# STM32L412C8T6 register map
File version: 1.0
STM32L412C8T6,STM32L412C8U6,STM32L412CBT3,STM32L412CBT3P,STM32L412CBT6,STM32L412CBT6P,STM32L412CBT7,STM32L412CBT7P,STM32L412CBU3,STM32L412CBU3P,STM32L412CBU6,STM32L412CBU6P,STM32L412CBU7,STM32L412CBU7P,STM32L412K8T6,STM32L412K8U6,STM32L412KBT3,STM32L412KBT6,STM32L412KBT7,STM32L412KBU3,STM32L412KBU6,STM32L412KBU7,STM32L412R8I6,STM32L412R8T6,STM32L412RBI6,STM32L412RBI6P,STM32L412RBT6,STM32L412RBT6P,STM32L412T8Y6,STM32L412TBY6,STM32L412TBY6P,STM32L422CBT6,STM32L422CBU6,STM32L422KBT6,STM32L422KBU6,STM32L422RBI6,STM32L422RBT6,STM32L422TBY6,STM32L431CBT6,STM32L431CBT7,STM32L431CBU6,STM32L431CBU7,STM32L431CBY6,STM32L431CBY7,STM32L431CCT6,STM32L431CCU6,STM32L431CCY6,STM32L431KBU6,STM32L431KCU6,STM32L431RBI3,STM32L431RBI6,STM32L431RBI7,STM32L431RBT3,STM32L431RBT6,STM32L431RBT7,STM32L431RBY3,STM32L431RBY6,STM32L431RBY7,STM32L431RCI6,STM32L431RCT6,STM32L431RCY6,STM32L431VCI6,STM32L431VCI7,STM32L431VCT6,STM32L431VCT7,STM32L432KBU6,STM32L432KCU6,STM32L433CBT6,STM32L433CBT7,STM32L433CBU6,STM32L433CBU7,STM32L433CBY6,STM32L433CBY7,STM32L433CCT3,STM32L433CCT6,STM32L433CCT7,STM32L433CCU3,STM32L433CCU6,STM32L433CCU7,STM32L433CCY3,STM32L433CCY6,STM32L433CCY7,STM32L433RBI6,STM32L433RBT6,STM32L433RBY6,STM32L433RCI3,STM32L433RCI6,STM32L433RCI7,STM32L433RCT3,STM32L433RCT3P,STM32L433RCT6,STM32L433RCT6P,STM32L433RCT7,STM32L433RCT7P,STM32L433RCY3,STM32L433RCY6,STM32L433RCY7,STM32L433VCI3,STM32L433VCI6,STM32L433VCI7,STM32L433VCT3,STM32L433VCT6,STM32L433VCT7,STM32L442KCU6,STM32L443CCF6,STM32L443CCT6,STM3
Registers are 32-bit, access not given, reset 0x0 unless marked. A register's access mark holds for its fields unless they carry their own. Offsets are from the block's base; lines under a group give offsets from that group; [hi:lo] are bit positions; {n}, {i} and the like mark numbered series; 'fields as' and 'values as' point back to an identical list; <NAME> marks a mode.

## Memory map
0x40000000 TIM2
0x40000400 TIM3
0x40001000 TIM6
0x40001400 TIM7
0x40002400 LCD
0x40002800 RTC
0x40002C00 WWDG
0x40003000 IWDG
0x40003800 SPI2
0x40003C00 SPI3
0x40004400 USART2
0x40004800 USART3
0x40004C00 USART4
0x40005400 I2C1
0x40005800 I2C2
0x40005C00 I2C3
0x40006000 CRS
0x40006400 CAN1
0x40006800 USBFS
0x40006C00 USBSRAM
0x40007000 PWR
0x40007400 DAC1
0x40007800 OPAMP
0x40007C00 LPTIM1
0x40008000 LPUART1
0x40008400 I2C4
0x40008800 SWPMI1
0x40009400 LPTIM2
0x40010000 SYSCFG
0x40010030 VREFBUF
0x40010200 COMP
0x40010400 EXTI
0x40011C00 FW
0x40012800 SDMMC
0x40012C00 TIM1
0x40013000 SPI1
0x40013800 USART1
0x40014000 TIM15
0x40014400 TIM16
0x40015400 SAI1
0x40016000 DFSDM1
0x40020000 DMA1
0x40020400 DMA2
0x40021000 RCC
0x40022000 FLASH
0x40023000 CRC
0x40024000 TSC
0x48000000 GPIOA
0x48000400 GPIOB
0x48000800 GPIOC
0x48000C00 GPIOD
0x48001000 GPIOE
0x48001C00 GPIOH
0x50040000 ADC
0x50060000 AES
0x50060800 RNG

## TIM2
Base 0x40000000
Same registers: LPTIM2 0x40009400
0x00 CR1
  [11] UIFREMAP, [31:10] s, [9:8] CKD, [7] ARPE, [6:5] CMS, [4] DIR, [3] OPM, [2] URS, [1] UDIS, [0] CEN
0x04 CR2
  [7] TI1S, [6:4] MMS, [3] CCDS, [31:0] s
0x08 SMCR
  [31:17] s, [15] ETP, [14] ECE, [13:12] ETPS, [11:8] ETF, [7] MSM, [6:4] TS, [3] OCCS, [16:0] SMS
0x0C DIER
  [14] TDE, [n+8] CC{n}DE (n=1..4), [8] UDE, [6] TIE, [31:5] s, [n] CC{n}IE (n=1..4), [0] UIE
0x10 SR
  [n+8] CC{n}OF (n=1..4), [6] TIF, [31:5] s, [n] CC{n}IF (n=1..4), [0] UIF
0x14 EGR
  [6] TG, [31:5] s, [n] CC{n}G (n=1..4), [0] UG
0x18 CCMR1_OUT
  [31:17] s, [15] OC2CE, [24:12] OC2M, [11] OC2PE, [10] OC2FE, [9:8] CC2S, [7] OC1CE, [16:4] OC1M, [3] OC1PE, [2] OC1FE, [1:0] CC1S
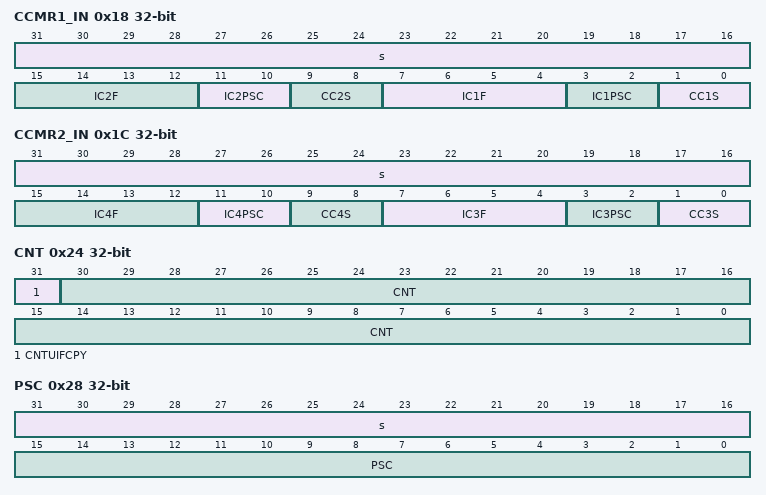
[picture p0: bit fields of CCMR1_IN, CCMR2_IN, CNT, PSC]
0x18 CCMR1_IN
  [31:16] s, [15:12] IC2F, [11:10] IC2PSC, [9:8] CC2S, [7:4] IC1F, [3:2] IC1PSC, [1:0] CC1S
0x1C CCMR2_OUT
  [31:17] s, [15] O24CE, [24:12] OC4M, [11] OC4PE, [10] OC4FE, [9:8] CC4S, [7] OC3CE, [16:4] OC3M, [3] OC3PE, [2] OC3FE, [1:0] CC3S
0x1C CCMR2_IN
  [31:16] s, [15:12] IC4F, [11:10] IC4PSC, [9:8] CC4S, [7:4] IC3F, [3:2] IC3PSC, [1:0] CC3S
0x20 CCER
  [4n-1] CC{n}NP (n=1..4), [4n-3] CC{n}P (n=1..4), [4n-4] CC{n}E (n=1..4), [31:2] s
0x24 CNT
  [31] CNTUIFCPY, [30:0] CNT
0x28 PSC
  [31:16] s, [15:0] PSC
0x2C ARR
{0x30+4i} CCR{i} (i=1..4)
0x48 DCR
  [12:8] DBL, [31:5] s, [4:0] DBA
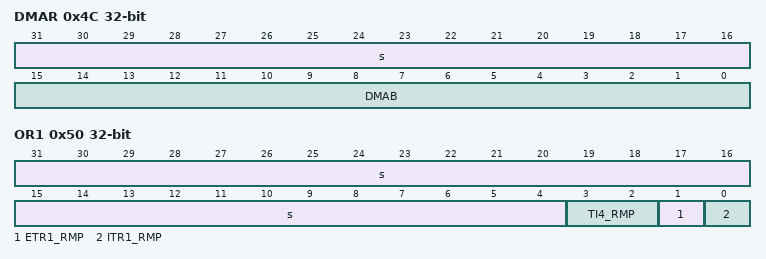
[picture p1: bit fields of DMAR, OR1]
0x4C DMAR
  [31:16] s, [15:0] DMAB
0x50 OR1
  [31:4] s, [3:2] TI4_RMP, [1] ETR1_RMP, [0] ITR1_RMP
0x60 OR2
  [16:14] ETRSEL, [31:0] s

## TIM3
Base 0x40000400
Registers as TIM2, without OR1, OR2.
